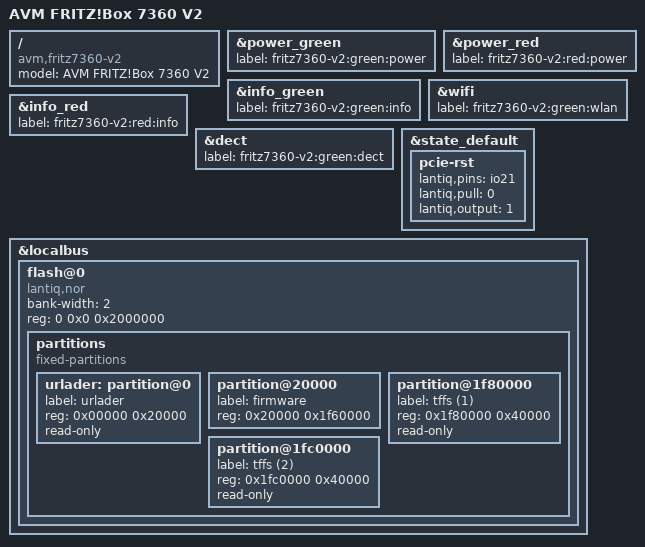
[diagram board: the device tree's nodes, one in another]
// SPDX-License-Identifier: GPL-2.0-or-later OR MIT
/dts-v1/;

#include "vr9_avm_fritz736x.dtsi"

#include <dt-bindings/input/input.h>
#include <dt-bindings/mips/lantiq_rcu_gphy.h>

/ {
	compatible = "avm,fritz7360-v2", "avm,fritz736x", "lantiq,xway", "lantiq,vr9";
	model = "AVM FRITZ!Box 7360 V2";
};

&power_green {
	label = "fritz7360-v2:green:power";
};

&power_red {
	label = "fritz7360-v2:red:power";
};

&info_green {
	label = "fritz7360-v2:green:info";
};

&wifi {
	label = "fritz7360-v2:green:wlan";
};

&info_red {
	label = "fritz7360-v2:red:info";
};

&dect {
	label = "fritz7360-v2:green:dect";
};

&state_default {
	pcie-rst {
		lantiq,pins = "io21";
		lantiq,pull = <0>;
		lantiq,output = <1>;
	};
};

&localbus {
	flash@0 {
		compatible = "lantiq,nor";
		bank-width = <2>;
		reg = <0 0x0 0x2000000>;

		partitions {
			#address-cells = <1>;
			#size-cells = <1>;
			compatible = "fixed-partitions";

			urlader: partition@0 {
				label = "urlader";
				reg = <0x00000 0x20000>;
				read-only;
			};

			partition@20000 {
				label = "firmware";
				reg = <0x20000 0x1f60000>;
			};

			partition@1f80000 {
				label = "tffs (1)";
				reg = <0x1f80000 0x40000>;
				read-only;
			};

			partition@1fc0000 {
				label = "tffs (2)";
				reg = <0x1fc0000 0x40000>;
				read-only;
			};
		};
	};
};
